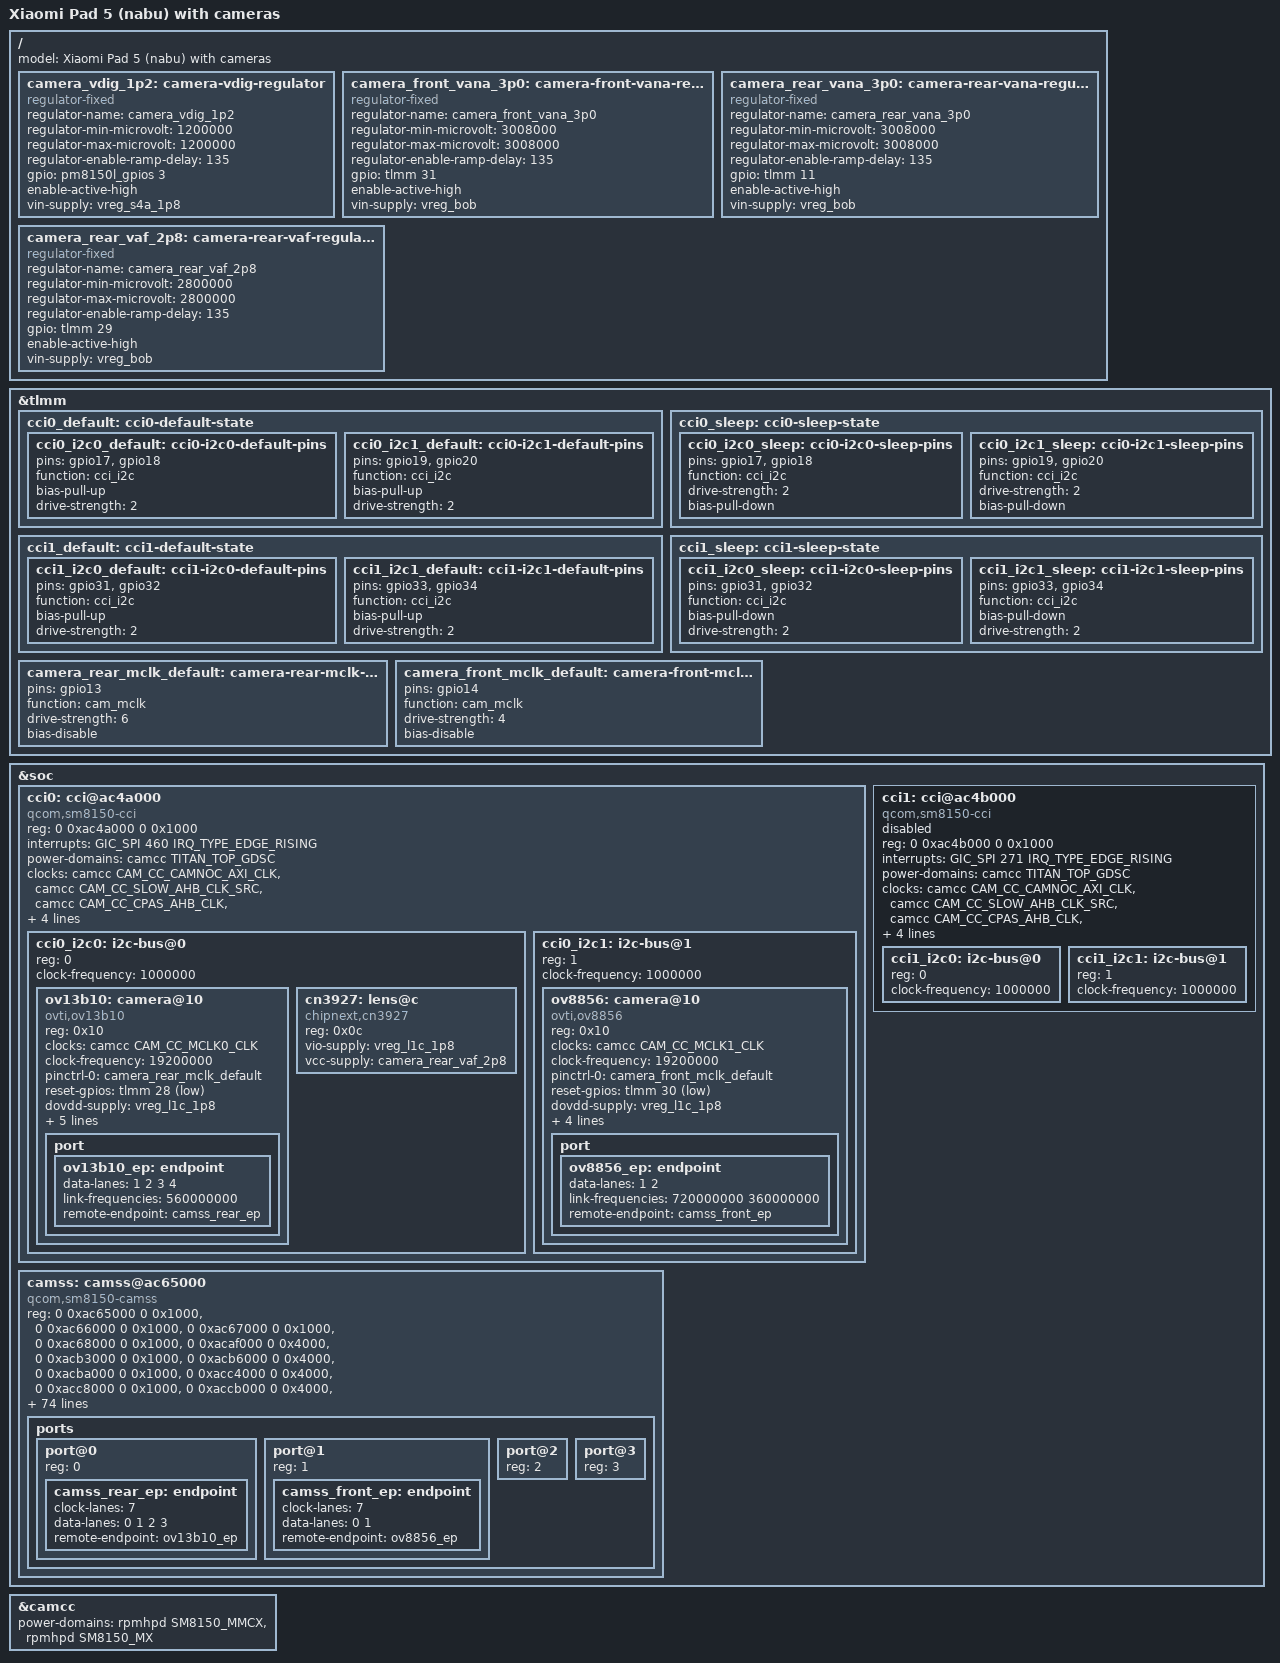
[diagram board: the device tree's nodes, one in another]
// SPDX-License-Identifier: BSD-3-Clause
/*
 * Camera additions for Xiaomi Pad 5 (nabu).
 *
 * This file deliberately appends to the base SM8150 and nabu device trees so
 * that sm8150.dtsi and sm8150-xiaomi-nabu.dts remain untouched.
 */

/ {
	model = "Xiaomi Pad 5 (nabu) with cameras";

	camera_vdig_1p2: camera-vdig-regulator {
		compatible = "regulator-fixed";
		regulator-name = "camera_vdig_1p2";
		regulator-min-microvolt = <1200000>;
		regulator-max-microvolt = <1200000>;
		regulator-enable-ramp-delay = <135>;
		gpio = <&pm8150l_gpios 3 GPIO_ACTIVE_HIGH>;
		enable-active-high;
		vin-supply = <&vreg_s4a_1p8>;
	};

	camera_front_vana_3p0: camera-front-vana-regulator {
		compatible = "regulator-fixed";
		regulator-name = "camera_front_vana_3p0";
		regulator-min-microvolt = <3008000>;
		regulator-max-microvolt = <3008000>;
		regulator-enable-ramp-delay = <135>;
		gpio = <&tlmm 31 GPIO_ACTIVE_HIGH>;
		enable-active-high;
		vin-supply = <&vreg_bob>;
	};

	camera_rear_vana_3p0: camera-rear-vana-regulator {
		compatible = "regulator-fixed";
		regulator-name = "camera_rear_vana_3p0";
		regulator-min-microvolt = <3008000>;
		regulator-max-microvolt = <3008000>;
		regulator-enable-ramp-delay = <135>;
		gpio = <&tlmm 11 GPIO_ACTIVE_HIGH>;
		enable-active-high;
		vin-supply = <&vreg_bob>;
	};

	camera_rear_vaf_2p8: camera-rear-vaf-regulator {
		compatible = "regulator-fixed";
		regulator-name = "camera_rear_vaf_2p8";
		regulator-min-microvolt = <2800000>;
		regulator-max-microvolt = <2800000>;
		regulator-enable-ramp-delay = <135>;
		gpio = <&tlmm 29 GPIO_ACTIVE_HIGH>;
		enable-active-high;
		vin-supply = <&vreg_bob>;
	};
};

&tlmm {
	cci0_default: cci0-default-state {
		cci0_i2c0_default: cci0-i2c0-default-pins {
			pins = "gpio17", "gpio18";
			function = "cci_i2c";
			bias-pull-up;
			drive-strength = <2>;
		};

		cci0_i2c1_default: cci0-i2c1-default-pins {
			pins = "gpio19", "gpio20";
			function = "cci_i2c";
			bias-pull-up;
			drive-strength = <2>;
		};
	};

	cci0_sleep: cci0-sleep-state {
		cci0_i2c0_sleep: cci0-i2c0-sleep-pins {
			pins = "gpio17", "gpio18";
			function = "cci_i2c";
			drive-strength = <2>;
			bias-pull-down;
		};

		cci0_i2c1_sleep: cci0-i2c1-sleep-pins {
			pins = "gpio19", "gpio20";
			function = "cci_i2c";
			drive-strength = <2>;
			bias-pull-down;
		};
	};

	cci1_default: cci1-default-state {
		cci1_i2c0_default: cci1-i2c0-default-pins {
			pins = "gpio31", "gpio32";
			function = "cci_i2c";
			bias-pull-up;
			drive-strength = <2>;
		};

		cci1_i2c1_default: cci1-i2c1-default-pins {
			pins = "gpio33", "gpio34";
			function = "cci_i2c";
			bias-pull-up;
			drive-strength = <2>;
		};
	};

	cci1_sleep: cci1-sleep-state {
		cci1_i2c0_sleep: cci1-i2c0-sleep-pins {
			pins = "gpio31", "gpio32";
			function = "cci_i2c";
			bias-pull-down;
			drive-strength = <2>;
		};

		cci1_i2c1_sleep: cci1-i2c1-sleep-pins {
			pins = "gpio33", "gpio34";
			function = "cci_i2c";
			bias-pull-down;
			drive-strength = <2>;
		};
	};

	camera_rear_mclk_default: camera-rear-mclk-default-state {
		pins = "gpio13";
		function = "cam_mclk";
		drive-strength = <6>;
		bias-disable;
	};

	camera_front_mclk_default: camera-front-mclk-default-state {
		pins = "gpio14";
		function = "cam_mclk";
		drive-strength = <4>;
		bias-disable;
	};
};

&soc {
	cci0: cci@ac4a000 {
		compatible = "qcom,sm8150-cci", "qcom,msm8996-cci";
		#address-cells = <1>;
		#size-cells = <0>;

		reg = <0 0xac4a000 0 0x1000>;
		interrupts = <GIC_SPI 460 IRQ_TYPE_EDGE_RISING>;
		power-domains = <&camcc TITAN_TOP_GDSC>;

		clocks = <&camcc CAM_CC_CAMNOC_AXI_CLK>,
			 <&camcc CAM_CC_SLOW_AHB_CLK_SRC>,
			 <&camcc CAM_CC_CPAS_AHB_CLK>,
			 <&camcc CAM_CC_CCI_0_CLK>,
			 <&camcc CAM_CC_CCI_0_CLK_SRC>;
		clock-names = "camnoc_axi",
			      "slow_ahb_src",
			      "cpas_ahb",
			      "cci",
			      "cci_src";

		pinctrl-0 = <&cci0_default>;
		pinctrl-1 = <&cci0_sleep>;
		pinctrl-names = "default", "sleep";

		status = "disabled";

		cci0_i2c0: i2c-bus@0 {
			reg = <0>;
			clock-frequency = <1000000>;
			#address-cells = <1>;
			#size-cells = <0>;
		};

		cci0_i2c1: i2c-bus@1 {
			reg = <1>;
			clock-frequency = <1000000>;
			#address-cells = <1>;
			#size-cells = <0>;
		};
	};

	cci1: cci@ac4b000 {
		compatible = "qcom,sm8150-cci", "qcom,msm8996-cci";
		#address-cells = <1>;
		#size-cells = <0>;

		reg = <0 0xac4b000 0 0x1000>;
		interrupts = <GIC_SPI 271 IRQ_TYPE_EDGE_RISING>;
		power-domains = <&camcc TITAN_TOP_GDSC>;

		clocks = <&camcc CAM_CC_CAMNOC_AXI_CLK>,
			 <&camcc CAM_CC_SLOW_AHB_CLK_SRC>,
			 <&camcc CAM_CC_CPAS_AHB_CLK>,
			 <&camcc CAM_CC_CCI_1_CLK>,
			 <&camcc CAM_CC_CCI_1_CLK_SRC>;
		clock-names = "camnoc_axi",
			      "slow_ahb_src",
			      "cpas_ahb",
			      "cci",
			      "cci_src";

		pinctrl-0 = <&cci1_default>;
		pinctrl-1 = <&cci1_sleep>;
		pinctrl-names = "default", "sleep";

		status = "disabled";

		cci1_i2c0: i2c-bus@0 {
			reg = <0>;
			clock-frequency = <1000000>;
			#address-cells = <1>;
			#size-cells = <0>;
		};

		cci1_i2c1: i2c-bus@1 {
			reg = <1>;
			clock-frequency = <1000000>;
			#address-cells = <1>;
			#size-cells = <0>;
		};
	};

	camss: camss@ac65000 {
		compatible = "qcom,sm8150-camss";
		status = "disabled";

		reg = <0 0xac65000 0 0x1000>,
		      <0 0xac66000 0 0x1000>,
		      <0 0xac67000 0 0x1000>,
		      <0 0xac68000 0 0x1000>,
		      <0 0xacaf000 0 0x4000>,
		      <0 0xacb3000 0 0x1000>,
		      <0 0xacb6000 0 0x4000>,
		      <0 0xacba000 0 0x1000>,
		      <0 0xacc4000 0 0x4000>,
		      <0 0xacc8000 0 0x1000>,
		      <0 0xaccb000 0 0x4000>,
		      <0 0xaccf000 0 0x1000>;

		reg-names = "csiphy0",
			    "csiphy1",
			    "csiphy2",
			    "csiphy3",
			    "vfe0",
			    "csid0",
			    "vfe1",
			    "csid1",
			    "vfe_lite0",
			    "csid_lite0",
			    "vfe_lite1",
			    "csid_lite1";

		interrupts = <GIC_SPI 477 IRQ_TYPE_EDGE_RISING>,
			     <GIC_SPI 478 IRQ_TYPE_EDGE_RISING>,
			     <GIC_SPI 479 IRQ_TYPE_EDGE_RISING>,
			     <GIC_SPI 448 IRQ_TYPE_EDGE_RISING>,
			     <GIC_SPI 465 IRQ_TYPE_EDGE_RISING>,
			     <GIC_SPI 464 IRQ_TYPE_EDGE_RISING>,
			     <GIC_SPI 467 IRQ_TYPE_EDGE_RISING>,
			     <GIC_SPI 466 IRQ_TYPE_EDGE_RISING>,
			     <GIC_SPI 469 IRQ_TYPE_EDGE_RISING>,
			     <GIC_SPI 468 IRQ_TYPE_EDGE_RISING>,
			     <GIC_SPI 360 IRQ_TYPE_EDGE_RISING>,
			     <GIC_SPI 359 IRQ_TYPE_EDGE_RISING>;

		interrupt-names = "csiphy0",
				  "csiphy1",
				  "csiphy2",
				  "csiphy3",
				  "vfe0",
				  "csid0",
				  "vfe1",
				  "csid1",
				  "vfe_lite0",
				  "csid_lite0",
				  "vfe_lite1",
				  "csid_lite1";

		power-domains = <&camcc IFE_0_GDSC>,
				<&camcc IFE_1_GDSC>,
				<&camcc TITAN_TOP_GDSC>;
		power-domain-names = "ife0", "ife1", "top";

		clocks = <&camcc CAM_CC_CAMNOC_AXI_CLK>,
			 <&camcc CAM_CC_CAMNOC_AXI_CLK_SRC>,
			 <&camcc CAM_CC_CPAS_AHB_CLK>,
			 <&camcc CAM_CC_CPHY_RX_CLK_SRC>,
			 <&camcc CAM_CC_CSIPHY0_CLK>,
			 <&camcc CAM_CC_CSI0PHYTIMER_CLK>,
			 <&camcc CAM_CC_CSI0PHYTIMER_CLK_SRC>,
			 <&camcc CAM_CC_CSIPHY1_CLK>,
			 <&camcc CAM_CC_CSI1PHYTIMER_CLK>,
			 <&camcc CAM_CC_CSI1PHYTIMER_CLK_SRC>,
			 <&camcc CAM_CC_CSIPHY2_CLK>,
			 <&camcc CAM_CC_CSI2PHYTIMER_CLK>,
			 <&camcc CAM_CC_CSI2PHYTIMER_CLK_SRC>,
			 <&camcc CAM_CC_CSIPHY3_CLK>,
			 <&camcc CAM_CC_CSI3PHYTIMER_CLK>,
			 <&camcc CAM_CC_CSI3PHYTIMER_CLK_SRC>,
			 <&camcc CAM_CC_IFE_0_AXI_CLK>,
			 <&camcc CAM_CC_IFE_0_CLK>,
			 <&camcc CAM_CC_IFE_0_CLK_SRC>,
			 <&camcc CAM_CC_IFE_0_CPHY_RX_CLK>,
			 <&camcc CAM_CC_IFE_0_CSID_CLK>,
			 <&camcc CAM_CC_IFE_0_CSID_CLK_SRC>,
			 <&camcc CAM_CC_IFE_1_AXI_CLK>,
			 <&camcc CAM_CC_IFE_1_CLK>,
			 <&camcc CAM_CC_IFE_1_CLK_SRC>,
			 <&camcc CAM_CC_IFE_1_CPHY_RX_CLK>,
			 <&camcc CAM_CC_IFE_1_CSID_CLK>,
			 <&camcc CAM_CC_IFE_1_CSID_CLK_SRC>,
			 <&camcc CAM_CC_IFE_LITE_0_CLK>,
			 <&camcc CAM_CC_IFE_LITE_0_CLK_SRC>,
			 <&camcc CAM_CC_IFE_LITE_0_CPHY_RX_CLK>,
			 <&camcc CAM_CC_IFE_LITE_0_CSID_CLK>,
			 <&camcc CAM_CC_IFE_LITE_0_CSID_CLK_SRC>,
			 <&camcc CAM_CC_IFE_LITE_1_CLK>,
			 <&camcc CAM_CC_IFE_LITE_1_CLK_SRC>,
			 <&camcc CAM_CC_IFE_LITE_1_CPHY_RX_CLK>,
			 <&camcc CAM_CC_IFE_LITE_1_CSID_CLK>,
			 <&camcc CAM_CC_IFE_LITE_1_CSID_CLK_SRC>,
			 <&camcc CAM_CC_SLOW_AHB_CLK_SRC>,
			 <&gcc GCC_CAMERA_AHB_CLK>,
			 <&gcc GCC_CAMERA_HF_AXI_CLK>,
			 <&gcc GCC_CAMERA_SF_AXI_CLK>;
		clock-names = "camnoc_axi",
			      "camnoc_axi_src",
			      "cpas_ahb",
			      "cphy_rx_src",
			      "csiphy0",
			      "csiphy0_timer",
			      "csiphy0_timer_src",
			      "csiphy1",
			      "csiphy1_timer",
			      "csiphy1_timer_src",
			      "csiphy2",
			      "csiphy2_timer",
			      "csiphy2_timer_src",
			      "csiphy3",
			      "csiphy3_timer",
			      "csiphy3_timer_src",
			      "vfe0_axi",
			      "vfe0",
			      "vfe0_src",
			      "vfe0_cphy_rx",
			      "vfe0_csid",
			      "vfe0_csid_src",
			      "vfe1_axi",
			      "vfe1",
			      "vfe1_src",
			      "vfe1_cphy_rx",
			      "vfe1_csid",
			      "vfe1_csid_src",
			      "vfe_lite0",
			      "vfe_lite0_src",
			      "vfe_lite0_cphy_rx",
			      "vfe_lite0_csid",
			      "vfe_lite0_csid_src",
			      "vfe_lite1",
			      "vfe_lite1_src",
			      "vfe_lite1_cphy_rx",
			      "vfe_lite1_csid",
			      "vfe_lite1_csid_src",
			      "slow_ahb_src",
			      "gcc_ahb",
			      "gcc_axi_hf",
			      "gcc_axi_sf";

		iommus = <&apps_smmu 0x840 0x620>,
			 <&apps_smmu 0x860 0x620>,
			 <&apps_smmu 0xA40 0x620>,
			 <&apps_smmu 0xA60 0x620>,
			 <&apps_smmu 0xC40 0x620>,
			 <&apps_smmu 0xC60 0x620>,
			 <&apps_smmu 0xE40 0x620>,
			 <&apps_smmu 0xE60 0x620>;

		interconnects = <&gem_noc MASTER_AMPSS_M0 0 &config_noc SLAVE_CAMERA_CFG 0>,
				<&mmss_noc MASTER_CAMNOC_HF0 0 &mc_virt SLAVE_EBI_CH0 0>,
				<&mmss_noc MASTER_CAMNOC_HF1 0 &mc_virt SLAVE_EBI_CH0 0>,
				<&mmss_noc MASTER_CAMNOC_SF 0 &mc_virt SLAVE_EBI_CH0 0>;
		interconnect-names = "cam_ahb",
				     "cam_hf_0_mnoc",
				     "cam_hf_1_mnoc",
				     "cam_sf_0_mnoc";

		ports {
			#address-cells = <1>;
			#size-cells = <0>;

			port@0 {
				reg = <0>;
			};

			port@1 {
				reg = <1>;
			};

			port@2 {
				reg = <2>;
			};

			port@3 {
				reg = <3>;
			};
		};
	};
};

&camcc {
	power-domains = <&rpmhpd SM8150_MMCX>, <&rpmhpd SM8150_MX>;
};

&camss {
	vdda-phy-supply = <&vreg_l5a_0p8>;
	vdda-pll-supply = <&vreg_l3c_1p2>;
	status = "okay";

	ports {
		port@0 {
			camss_rear_ep: endpoint {
				status = "okay";
				clock-lanes = <7>;
				data-lanes = <0 1 2 3>;
				remote-endpoint = <&ov13b10_ep>;
			};
		};

		port@1 {
			camss_front_ep: endpoint {
				clock-lanes = <7>;
				data-lanes = <0 1>;
				remote-endpoint = <&ov8856_ep>;
			};
		};
	};
};

&cci0 {
	status = "okay";
};

&cci0_i2c0 {
	ov13b10: camera@10 {
		compatible = "ovti,ov13b10";
		reg = <0x10>;
		status = "okay";

		clocks = <&camcc CAM_CC_MCLK0_CLK>;
		clock-names = "xvclk";
		clock-frequency = <19200000>;

		pinctrl-0 = <&camera_rear_mclk_default>;
		pinctrl-names = "default";
		reset-gpios = <&tlmm 28 GPIO_ACTIVE_LOW>;

		dovdd-supply = <&vreg_l1c_1p8>;
		avdd-supply = <&camera_rear_vana_3p0>;
		dvdd-supply = <&camera_vdig_1p2>;
		lens-focus = <&cn3927>;

		orientation = <1>;
		rotation = <270>;

		port {
			ov13b10_ep: endpoint {
				data-lanes = <1 2 3 4>;
				link-frequencies = /bits/ 64 <560000000>;
				remote-endpoint = <&camss_rear_ep>;
			};
		};
	};

	cn3927: lens@c {
		compatible = "chipnext,cn3927";
		reg = <0x0c>;
		vio-supply = <&vreg_l1c_1p8>;
		vcc-supply = <&camera_rear_vaf_2p8>;
	};
};

&cci0_i2c1 {
	ov8856: camera@10 {
		compatible = "ovti,ov8856";
		reg = <0x10>;

		clocks = <&camcc CAM_CC_MCLK1_CLK>;
		clock-names = "xvclk";
		clock-frequency = <19200000>;

		pinctrl-0 = <&camera_front_mclk_default>;
		pinctrl-names = "default";
		reset-gpios = <&tlmm 30 GPIO_ACTIVE_LOW>;

		dovdd-supply = <&vreg_l1c_1p8>;
		avdd-supply = <&camera_front_vana_3p0>;
		dvdd-supply = <&camera_vdig_1p2>;

		orientation = <0>;
		rotation = <270>;

		port {
			ov8856_ep: endpoint {
				data-lanes = <1 2>;
				link-frequencies = /bits/ 64 <720000000 360000000>;
				remote-endpoint = <&camss_front_ep>;
			};
		};
	};
};
